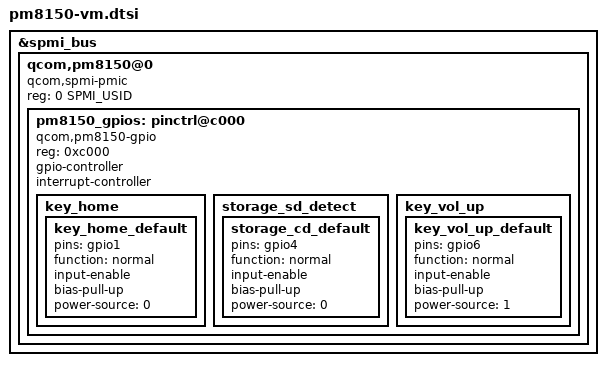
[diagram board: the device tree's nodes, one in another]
#include <dt-bindings/input/input.h>
#include <dt-bindings/input/qcom,qpnp-power-on.h>
#include <dt-bindings/spmi/spmi.h>
#include <dt-bindings/iio/qcom,spmi-vadc.h>

&spmi_bus {
	qcom,pm8150@0 {
		compatible = "qcom,spmi-pmic";
		reg = <0 SPMI_USID>;
		#address-cells = <1>;
		#size-cells = <0>;

		pm8150_gpios: pinctrl@c000 {
			compatible = "qcom,pm8150-gpio";
			reg = <0xc000>;
			gpio-controller;
			#gpio-cells = <2>;
			interrupt-controller;
			#interrupt-cells = <2>;
		};
	};
};

&pm8150_gpios {
	key_home {
		key_home_default: key_home_default {
			pins = "gpio1";
			function = "normal";
			input-enable;
			bias-pull-up;
			power-source = <0>;
		};
	};

	storage_sd_detect {
		storage_cd_default: storage_cd_default {
			pins = "gpio4";
			function = "normal";
			input-enable;
			bias-pull-up;
			power-source = <0>;
		};
	};

	key_vol_up {
		key_vol_up_default: key_vol_up_default {
			pins = "gpio6";
			function = "normal";
			input-enable;
			bias-pull-up;
			power-source = <1>;
		};
	};
};
